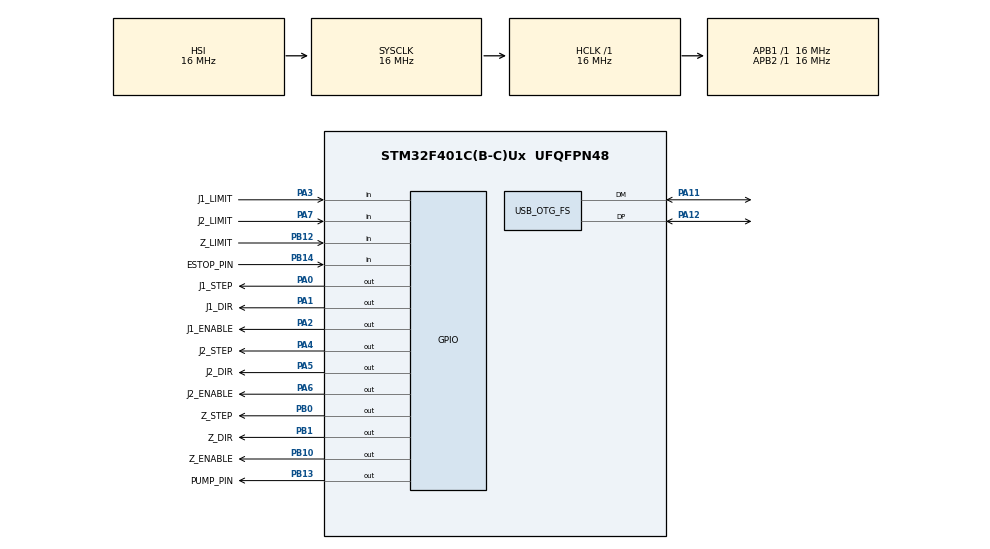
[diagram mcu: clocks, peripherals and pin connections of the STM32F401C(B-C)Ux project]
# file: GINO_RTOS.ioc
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FREERTOS.Queues01=CommandQueue,10,20,1,Dynamic,NULL,NULL
FREERTOS.Tasks01=DispatcherTask,32,512,StartDefaultTask,Default,NULL,Dynamic,NULL,NULL;MotorTask,40,512,StartMotorTask,Default,NULL,Dynamic,NULL,NULL;KinematicsTask,24,512,StartKinematicsTask,Default,NULL,Dynamic,NULL,NULL;CommTask,16,512,StartCommTask,Default,NULL,Dynamic,NULL,NULL;ToolTask,24,256,StartToolTask,Default,NULL,Dynamic,NULL,NULL
Mcu.Family=STM32F4
Mcu.Name=STM32F401C(B-C)Ux
Mcu.Package=UFQFPN48
NVIC.OTG_FS_IRQn=true\:5\:0\:false\:false\:true\:true\:false\:true\:true
NVIC.PriorityGroup=NVIC_PRIORITYGROUP_4
NVIC.TIM1_UP_TIM10_IRQn=true\:15\:0\:false\:false\:true\:false\:false\:true\:true
NVIC.TimeBase=TIM1_UP_TIM10_IRQn
NVIC.TimeBaseIP=TIM1
PA0-WKUP.GPIO_Label=J1_STEP
PA0-WKUP.Signal=GPIO_Output
PA1.GPIO_Label=J1_DIR
PA1.Signal=GPIO_Output
PA11.Mode=Device_Only
PA11.Signal=USB_OTG_FS_DM
PA12.Mode=Device_Only
PA12.Signal=USB_OTG_FS_DP
PA2.GPIO_Label=J1_ENABLE
PA2.Signal=GPIO_Output
PA3.GPIO_Label=J1_LIMIT
PA3.GPIO_PuPd=GPIO_PULLUP
PA3.Signal=GPIO_Input
PA4.GPIO_Label=J2_STEP
PA4.Signal=GPIO_Output
PA5.GPIO_Label=J2_DIR
PA5.Signal=GPIO_Output
PA6.GPIO_Label=J2_ENABLE
PA6.Signal=GPIO_Output
PA7.GPIO_Label=J2_LIMIT
PA7.GPIO_PuPd=GPIO_PULLUP
PA7.Signal=GPIO_Input
PB0.GPIO_Label=Z_STEP
PB0.Signal=GPIO_Output
PB1.GPIO_Label=Z_DIR
PB1.Signal=GPIO_Output
PB10.GPIO_Label=Z_ENABLE
PB10.Signal=GPIO_Output
PB12.GPIO_Label=Z_LIMIT
PB12.GPIO_PuPd=GPIO_PULLUP
PB12.Signal=GPIO_Input
PB13.GPIO_Label=PUMP_PIN
PB13.Signal=GPIO_Output
PB14.GPIO_Label=ESTOP_PIN
PB14.GPIO_PuPd=GPIO_PULLUP
PB14.Signal=GPIO_Input
PH0\ -\ OSC_IN.Mode=HSE-External-Oscillator
PH0\ -\ OSC_IN.Signal=RCC_OSC_IN
PH1\ -\ OSC_OUT.Mode=HSE-External-Oscillator
PH1\ -\ OSC_OUT.Signal=RCC_OSC_OUT
ProjectManager.HeapSize=0x200
ProjectManager.StackSize=0x400
ProjectManager.TargetToolchain=CMake
RCC.48MHZClocksFreq_Value=48000000
RCC.AHBFreq_Value=16000000
RCC.APB1Freq_Value=16000000
RCC.APB2Freq_Value=16000000
RCC.CortexFreq_Value=16000000
RCC.HSE_VALUE=25000000
RCC.HSI_VALUE=16000000
RCC.LSE_VALUE=32768
RCC.PLLM=15
RCC.PLLN=144
RCC.PLLQ=5
RCC.SYSCLKFreq_VALUE=16000000
RCC.VCOOutputFreq_Value=240000000
USB_DEVICE.CLASS_NAME_FS=CDC
USB_DEVICE.VirtualMode=Cdc
USB_DEVICE.VirtualModeFS=Cdc_FS
USB_OTG_FS.VirtualMode=Device_Only
VP_FREERTOS_VS_CMSIS_V2.Mode=CMSIS_V2
VP_SYS_VS_tim1.Mode=TIM1
VP_USB_DEVICE_VS_USB_DEVICE_CDC_FS.Mode=CDC_FS
board=custom

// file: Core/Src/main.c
/* USER CODE BEGIN Header */
/**
  ******************************************************************************
  * @file           : main.c
  * @brief          : Main program body
  ******************************************************************************
  * @attention
  *
  * Copyright (c) 2026 STMicroelectronics.
  * All rights reserved.
  *
  * This software is licensed under terms that can be found in the LICENSE file
  * in the root directory of this software component.
  * If no LICENSE file comes with this software, it is provided AS-IS.
  *
  ******************************************************************************
  */
/* USER CODE END Header */
#include "main.h"
#include "cmsis_os.h"
#include "usb_device.h"
#include "gpio.h"

void SystemClock_Config(void);
void MX_FREERTOS_Init(void);

int main(void)
{

  /* MCU Configuration--------------------------------------------------------*/

  /* Reset of all peripherals, Initializes the Flash interface and the Systick. */
  HAL_Init();

  /* Configure the system clock */
  SystemClock_Config();

  /* Initialize all configured peripherals */
  MX_GPIO_Init();

  /* Init scheduler */
  osKernelInitialize();  /* Call init function for freertos objects (in cmsis_os2.c) */
  MX_FREERTOS_Init();

  /* Start scheduler */
  osKernelStart();

  /* We should never get here as control is now taken by the scheduler */

  /* Infinite loop */
  while (1)
  {

  }
}

void SystemClock_Config(void)
{
  RCC_OscInitTypeDef RCC_OscInitStruct = {0};
  RCC_ClkInitTypeDef RCC_ClkInitStruct = {0};

  /** Configure the main internal regulator output voltage
  */
  __HAL_RCC_PWR_CLK_ENABLE();
  __HAL_PWR_VOLTAGESCALING_CONFIG(PWR_REGULATOR_VOLTAGE_SCALE2);

  /** Initializes the RCC Oscillators according to the specified parameters
  * in the RCC_OscInitTypeDef structure.
  */
  RCC_OscInitStruct.OscillatorType = RCC_OSCILLATORTYPE_HSI|RCC_OSCILLATORTYPE_HSE;
  RCC_OscInitStruct.HSEState = RCC_HSE_ON;
  RCC_OscInitStruct.HSIState = RCC_HSI_ON;
  RCC_OscInitStruct.HSICalibrationValue = RCC_HSICALIBRATION_DEFAULT;
  RCC_OscInitStruct.PLL.PLLState = RCC_PLL_ON;
  RCC_OscInitStruct.PLL.PLLSource = RCC_PLLSOURCE_HSE;
  RCC_OscInitStruct.PLL.PLLM = 15;
  RCC_OscInitStruct.PLL.PLLN = 144;
  RCC_OscInitStruct.PLL.PLLP = RCC_PLLP_DIV2;
  RCC_OscInitStruct.PLL.PLLQ = 5;
  if (HAL_RCC_OscConfig(&RCC_OscInitStruct) != HAL_OK)
  {
    Error_Handler();
  }

  /** Initializes the CPU, AHB and APB buses clocks
  */
  RCC_ClkInitStruct.ClockType = RCC_CLOCKTYPE_HCLK|RCC_CLOCKTYPE_SYSCLK
                              |RCC_CLOCKTYPE_PCLK1|RCC_CLOCKTYPE_PCLK2;
  RCC_ClkInitStruct.SYSCLKSource = RCC_SYSCLKSOURCE_HSI;
  RCC_ClkInitStruct.AHBCLKDivider = RCC_SYSCLK_DIV1;
  RCC_ClkInitStruct.APB1CLKDivider = RCC_HCLK_DIV1;
  RCC_ClkInitStruct.APB2CLKDivider = RCC_HCLK_DIV1;

  if (HAL_RCC_ClockConfig(&RCC_ClkInitStruct, FLASH_LATENCY_0) != HAL_OK)
  {
    Error_Handler();
  }
}

void HAL_TIM_PeriodElapsedCallback(TIM_HandleTypeDef *htim)
{
  if (htim->Instance == TIM1)
  {
    HAL_IncTick();
  }
}

void Error_Handler(void)
{
  __disable_irq();
  while (1)
  {
  }
}

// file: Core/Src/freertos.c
/* USER CODE BEGIN Header */
/**
  ******************************************************************************
  * File Name          : freertos.c
  * Description        : Code for freertos applications
  ******************************************************************************
  * @attention
  *
  * Copyright (c) 2026 STMicroelectronics.
  * All rights reserved.
  *
  * This software is licensed under terms that can be found in the LICENSE file
  * in the root directory of this software component.
  * If no LICENSE file comes with this software, it is provided AS-IS.
  *
  ******************************************************************************
  */
/* USER CODE END Header */

#include "FreeRTOS.h"
#include "task.h"
#include "main.h"
#include "cmsis_os.h"

/* USER CODE BEGIN Includes */
#include "system_state.h"
#include "tmc2209_stepper.h"
#include "tool_controller.h"

/* USER CODE END Includes */

/* Definitions for DispatcherTask */
osThreadId_t DispatcherTaskHandle;
const osThreadAttr_t DispatcherTask_attributes = {
  .name = "DispatcherTask",
  .stack_size = 512 * 4,
  .priority = (osPriority_t) osPriorityAboveNormal,
};
/* Definitions for MotorTask */
osThreadId_t MotorTaskHandle;
const osThreadAttr_t MotorTask_attributes = {
  .name = "MotorTask",
  .stack_size = 512 * 4,
  .priority = (osPriority_t) osPriorityHigh,
};
/* Definitions for KinematicsTask */
osThreadId_t KinematicsTaskHandle;
const osThreadAttr_t KinematicsTask_attributes = {
  .name = "KinematicsTask",
  .stack_size = 512 * 4,
  .priority = (osPriority_t) osPriorityNormal,
};
/* Definitions for CommTask */
osThreadId_t CommTaskHandle;
const osThreadAttr_t CommTask_attributes = {
  .name = "CommTask",
  .stack_size = 512 * 4,
  .priority = (osPriority_t) osPriorityBelowNormal,
};
/* Definitions for ToolTask */
osThreadId_t ToolTaskHandle;
const osThreadAttr_t ToolTask_attributes = {
  .name = "ToolTask",
  .stack_size = 256 * 4,
  .priority = (osPriority_t) osPriorityNormal,
};
/* Definitions for CommandQueue */
osMessageQueueId_t CommandQueueHandle;
const osMessageQueueAttr_t CommandQueue_attributes = {
  .name = "CommandQueue"
};

void StartDefaultTask(void *argument);
void StartMotorTask(void *argument);
void StartKinematicsTask(void *argument);
void StartCommTask(void *argument);
void StartToolTask(void *argument);

extern void MX_USB_DEVICE_Init(void);
void MX_FREERTOS_Init(void); /* (MISRA C 2004 rule 8.1) */

void MX_FREERTOS_Init(void) {

  /* Create the queue(s) */
  /* creation of CommandQueue */
  CommandQueueHandle = osMessageQueueNew (10, 20, &CommandQueue_attributes);

  /* Create the thread(s) */
  /* creation of DispatcherTask */
  DispatcherTaskHandle = osThreadNew(StartDefaultTask, NULL, &DispatcherTask_attributes);

  /* creation of MotorTask */
  MotorTaskHandle = osThreadNew(StartMotorTask, NULL, &MotorTask_attributes);

  /* creation of KinematicsTask */
  KinematicsTaskHandle = osThreadNew(StartKinematicsTask, NULL, &KinematicsTask_attributes);

  /* creation of CommTask */
  CommTaskHandle = osThreadNew(StartCommTask, NULL, &CommTask_attributes);

  /* creation of ToolTask */
  ToolTaskHandle = osThreadNew(StartToolTask, NULL, &ToolTask_attributes);

}

void StartDefaultTask(void *argument)
{
  /* init code for USB_DEVICE */
  MX_USB_DEVICE_Init();
  for(;;)
  {
    osDelay(1);
  }
}

void StartMotorTask(void *argument)
{
  for(;;)
  {
    osDelay(1);
  }
}

void StartKinematicsTask(void *argument)
{
  for(;;)
  {
    osDelay(1);
  }
}

void StartCommTask(void *argument)
{
  for(;;)
  {
    osDelay(1);
  }
}

void StartToolTask(void *argument)
{
  for(;;)
  {
    osDelay(1);
  }
}
